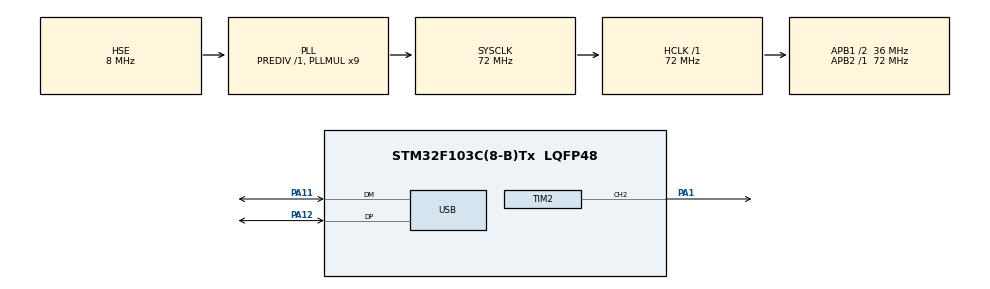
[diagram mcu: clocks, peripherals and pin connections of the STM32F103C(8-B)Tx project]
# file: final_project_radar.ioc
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Mcu.Family=STM32F1
Mcu.Name=STM32F103C(8-B)Tx
Mcu.Package=LQFP48
NVIC.PriorityGroup=NVIC_PRIORITYGROUP_4
NVIC.USB_LP_CAN1_RX0_IRQn=true\:0\:0\:false\:false\:true\:false\:true\:true
PA1.Signal=S_TIM2_CH2
PA11.Mode=Device
PA11.Signal=USB_DM
PA12.Mode=Device
PA12.Signal=USB_DP
PD0-OSC_IN.Mode=HSE-External-Oscillator
PD0-OSC_IN.Signal=RCC_OSC_IN
PD1-OSC_OUT.Mode=HSE-External-Oscillator
PD1-OSC_OUT.Signal=RCC_OSC_OUT
ProjectManager.HeapSize=0x200
ProjectManager.StackSize=0x400
ProjectManager.TargetToolchain=STM32CubeIDE
RCC.AHBFreq_Value=72000000
RCC.APB1CLKDivider=RCC_HCLK_DIV2
RCC.APB1Freq_Value=36000000
RCC.APB1TimFreq_Value=72000000
RCC.APB2Freq_Value=72000000
RCC.APB2TimFreq_Value=72000000
RCC.HCLKFreq_Value=72000000
RCC.PLLMUL=RCC_PLL_MUL9
RCC.SYSCLKFreq_VALUE=72000000
RCC.SYSCLKSource=RCC_SYSCLKSOURCE_PLLCLK
RCC.USBFreq_Value=48000000
RCC.USBPrescaler=RCC_USBCLKSOURCE_PLL_DIV1_5
SH.S_TIM2_CH2.0=TIM2_CH2,PWM Generation2 CH2
TIM2.Channel-PWM\ Generation2\ CH2=TIM_CHANNEL_2
TIM2.Period=24999
TIM2.Prescaler=71
USB_DEVICE.CLASS_NAME_FS=CDC
USB_DEVICE.VirtualMode=Cdc
USB_DEVICE.VirtualModeFS=Cdc_FS
VP_SYS_VS_ND.Mode=No_Debug
VP_TIM2_VS_ClockSourceINT.Mode=Internal
VP_USB_DEVICE_VS_USB_DEVICE_CDC_FS.Mode=CDC_FS
board=custom

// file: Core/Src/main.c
/* USER CODE BEGIN Header */
/**
  ******************************************************************************
  * @file           : main.c
  * @brief          : Main program body
  ******************************************************************************
  * @attention
  *
  * Copyright (c) 2025 STMicroelectronics.
  * All rights reserved.
  *
  * This software is licensed under terms that can be found in the LICENSE file
  * in the root directory of this software component.
  * If no LICENSE file comes with this software, it is provided AS-IS.
  *
  ******************************************************************************
  */
/* USER CODE END Header */
#include "main.h"
#include "usb_device.h"

/* USER CODE BEGIN Includes */
#include <stdbool.h>

/* USER CODE END Includes */

TIM_HandleTypeDef htim2;

void SystemClock_Config(void);
static void MX_GPIO_Init(void);
static void MX_TIM2_Init(void);

/* USER CODE BEGIN 0 */
bool clockwise = true; // Variable to control the direction of the motor
uint16_t pwm_value = 0; // Variable to store the PWM value

/* USER CODE END 0 */

int main(void)
{

  /* MCU Configuration--------------------------------------------------------*/

  /* Reset of all peripherals, Initializes the Flash interface and the Systick. */
  HAL_Init();

  /* Configure the system clock */
  SystemClock_Config();

  /* Initialize all configured peripherals */
  MX_GPIO_Init();
  MX_USB_DEVICE_Init();
  MX_TIM2_Init();
  /* USER CODE BEGIN 2 */
  HAL_TIM_PWM_Start(&htim2, TIM_CHANNEL_2);

  /* USER CODE END 2 */

  /* Infinite loop */
  while (1)
  {

    /* USER CODE BEGIN 3 */
    __HAL_TIM_SET_COMPARE(&htim2,TIM_CHANNEL_2, pwm_value);
    HAL_Delay(1);

    if (pwm_value % 100 == 0)
    {
      char buffer[50];
      int len = snprintf(buffer, sizeof(buffer), "PWM value: %d\n\r", pwm_value);
      CDC_Transmit_FS((uint8_t *)buffer, len);
      //HAL_Delay(10); // Delay to allow for USB transmission
    }

    if (clockwise) {
      pwm_value++; // Increase the PWM value for clockwise rotation
      if (pwm_value >= 2500) {
        clockwise = false; // Change direction to counter-clockwise
      }
    }  else {
      pwm_value--; // Decrease the PWM value for counter-clockwise rotation
      if (pwm_value <= 500) {
        clockwise = true; // Change direction to clockwise
      }
    }

  }
  /* USER CODE END 3 */
}

void SystemClock_Config(void)
{
  RCC_OscInitTypeDef RCC_OscInitStruct = {0};
  RCC_ClkInitTypeDef RCC_ClkInitStruct = {0};
  RCC_PeriphCLKInitTypeDef PeriphClkInit = {0};

  /** Initializes the RCC Oscillators according to the specified parameters
  * in the RCC_OscInitTypeDef structure.
  */
  RCC_OscInitStruct.OscillatorType = RCC_OSCILLATORTYPE_HSE;
  RCC_OscInitStruct.HSEState = RCC_HSE_ON;
  RCC_OscInitStruct.HSEPredivValue = RCC_HSE_PREDIV_DIV1;
  RCC_OscInitStruct.HSIState = RCC_HSI_ON;
  RCC_OscInitStruct.PLL.PLLState = RCC_PLL_ON;
  RCC_OscInitStruct.PLL.PLLSource = RCC_PLLSOURCE_HSE;
  RCC_OscInitStruct.PLL.PLLMUL = RCC_PLL_MUL9;
  if (HAL_RCC_OscConfig(&RCC_OscInitStruct) != HAL_OK)
  {
    Error_Handler();
  }

  /** Initializes the CPU, AHB and APB buses clocks
  */
  RCC_ClkInitStruct.ClockType = RCC_CLOCKTYPE_HCLK|RCC_CLOCKTYPE_SYSCLK
                              |RCC_CLOCKTYPE_PCLK1|RCC_CLOCKTYPE_PCLK2;
  RCC_ClkInitStruct.SYSCLKSource = RCC_SYSCLKSOURCE_PLLCLK;
  RCC_ClkInitStruct.AHBCLKDivider = RCC_SYSCLK_DIV1;
  RCC_ClkInitStruct.APB1CLKDivider = RCC_HCLK_DIV2;
  RCC_ClkInitStruct.APB2CLKDivider = RCC_HCLK_DIV1;

  if (HAL_RCC_ClockConfig(&RCC_ClkInitStruct, FLASH_LATENCY_2) != HAL_OK)
  {
    Error_Handler();
  }
  PeriphClkInit.PeriphClockSelection = RCC_PERIPHCLK_USB;
  PeriphClkInit.UsbClockSelection = RCC_USBCLKSOURCE_PLL_DIV1_5;
  if (HAL_RCCEx_PeriphCLKConfig(&PeriphClkInit) != HAL_OK)
  {
    Error_Handler();
  }
}

static void MX_TIM2_Init(void)
{

  TIM_ClockConfigTypeDef sClockSourceConfig = {0};
  TIM_MasterConfigTypeDef sMasterConfig = {0};
  TIM_OC_InitTypeDef sConfigOC = {0};

  htim2.Instance = TIM2;
  htim2.Init.Prescaler = 71;
  htim2.Init.CounterMode = TIM_COUNTERMODE_UP;
  htim2.Init.Period = 24999;
  htim2.Init.ClockDivision = TIM_CLOCKDIVISION_DIV1;
  htim2.Init.AutoReloadPreload = TIM_AUTORELOAD_PRELOAD_DISABLE;
  if (HAL_TIM_Base_Init(&htim2) != HAL_OK)
  {
    Error_Handler();
  }
  sClockSourceConfig.ClockSource = TIM_CLOCKSOURCE_INTERNAL;
  if (HAL_TIM_ConfigClockSource(&htim2, &sClockSourceConfig) != HAL_OK)
  {
    Error_Handler();
  }
  if (HAL_TIM_PWM_Init(&htim2) != HAL_OK)
  {
    Error_Handler();
  }
  sMasterConfig.MasterOutputTrigger = TIM_TRGO_RESET;
  sMasterConfig.MasterSlaveMode = TIM_MASTERSLAVEMODE_DISABLE;
  if (HAL_TIMEx_MasterConfigSynchronization(&htim2, &sMasterConfig) != HAL_OK)
  {
    Error_Handler();
  }
  sConfigOC.OCMode = TIM_OCMODE_PWM1;
  sConfigOC.Pulse = 0;
  sConfigOC.OCPolarity = TIM_OCPOLARITY_HIGH;
  sConfigOC.OCFastMode = TIM_OCFAST_DISABLE;
  if (HAL_TIM_PWM_ConfigChannel(&htim2, &sConfigOC, TIM_CHANNEL_2) != HAL_OK)
  {
    Error_Handler();
  }
  HAL_TIM_MspPostInit(&htim2);

}

static void MX_GPIO_Init(void)
{

  /* GPIO Ports Clock Enable */
  __HAL_RCC_GPIOD_CLK_ENABLE();
  __HAL_RCC_GPIOA_CLK_ENABLE();

}

void Error_Handler(void)
{
  __disable_irq();
  while (1)
  {
  }
}
